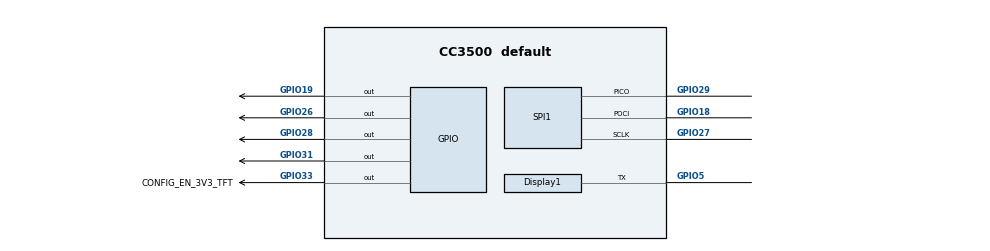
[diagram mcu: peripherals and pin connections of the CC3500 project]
/**
 * @cliArgs --device "CC3500" --part "Default" --package "default" --rtos "freertos" --product "simplelink_wifi_sdk@9.22.00.15" --product "TOOLBOX@4.1.8"
 * @versions {"tool":"1.27.0+4565"}
 */

/**
 * Import the modules used in this configuration.
 */
const FreeRTOS  = scripting.addModule("/freertos/FreeRTOS");
const Display   = scripting.addModule("/ti/display/Display");
const Display1  = Display.addInstance();
const GPIO      = scripting.addModule("/ti/drivers/GPIO");
const GPIO2     = GPIO.addInstance();
const GPIO3     = GPIO.addInstance();
const GPIO4     = GPIO.addInstance();
const GPIO5     = GPIO.addInstance();
const GPIO6     = GPIO.addInstance();
const GPIO10    = GPIO.addInstance();
const Power     = scripting.addModule("/ti/drivers/Power");
const SPI       = scripting.addModule("/ti/drivers/SPI");
const SPI1      = SPI.addInstance();
const Mem_cfg   = scripting.addModule("/ti/memoryconfig/MemoryConfigurator/Mem_cfg");
const Settings  = scripting.addModule("/ti/posix/freertos/Settings");
const ActionReq = scripting.addModule("/ti/vendorutils/Action/ActionReq");

/**
 * Write custom configuration values to the imported modules.
 */
Display1.$name                   = "CONFIG_Display_0";
Display1.uart.$name              = "CONFIG_UART2_0";
Display1.uart.uart.$assign       = "UART1";
Display1.uart.uart.txPin.$assign = "GPIO5";

GPIO2.$name           = "CONFIG_GPIO_LCD_CS";
GPIO2.mode            = "Output";
GPIO2.gpioPin.$assign = "GPIO26";

GPIO3.$name           = "CONFIG_GPIO_LCD_DC";
GPIO3.mode            = "Output";
GPIO3.gpioPin.$assign = "GPIO28";

GPIO4.$name           = "CONFIG_GPIO_LCD_RST";
GPIO4.mode            = "Output";
GPIO4.gpioPin.$assign = "GPIO31";

GPIO5.$name           = "CONFIG_GPIO_TRACE";
GPIO5.mode            = "Output";
GPIO5.gpioPin.$assign = "GPIO19";

GPIO6.$name           = "CONFIG_EN_3V3_TFT";
GPIO6.mode            = "Output";
GPIO6.gpioPin.$assign = "GPIO33";

GPIO10.$name = "CONFIG_PWM_BLK";
GPIO10.mode  = "Output";

Power.policyFunction = "PowerWFF3_doWFI";

SPI1.$name                    = "CONFIG_SPI_LCD";
SPI1.spi.$assign              = "SPI0";
SPI1.spi.sclkPin.$assign      = "GPIO27";
SPI1.spi.dmaRxChannel.$assign = "DMA_CH11";
SPI1.spi.dmaTxChannel.$assign = "DMA_CH10";
SPI1.spi.pociPin.$assign      = "GPIO18";
SPI1.spi.picoPin.$assign      = "GPIO29";

Mem_cfg.flash_device_type = "PY25Q128LA";
Mem_cfg.psram_type        = "STACKED_PSRAM_AP_8M";
Mem_cfg.ota               = false;
scripting.suppress("Selecting this option means that a PSRAM is mandatory\\.", Mem_cfg, "psram_type");

ActionReq.activation_type = "authentication_bypass";

/**
 * Pinmux solution for unlocked pins/peripherals. This ensures that minor changes to the automatic solver in a future
 * version of the tool will not impact the pinmux you originally saw.  These lines can be completely deleted in order to
 * re-solve from scratch.
 */
Display1.uart.uart.dmaTxChannel.$suggestSolution = "DMA_CH1";
Display1.uart.uart.dmaRxChannel.$suggestSolution = "DMA_CH0";
GPIO10.gpioPin.$suggestSolution                  = "GPIO35";
